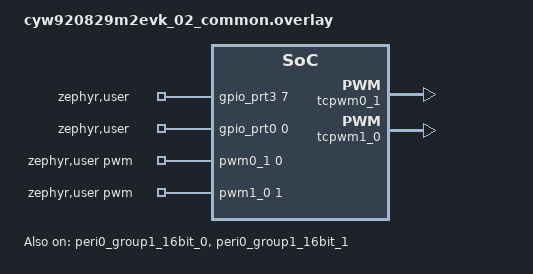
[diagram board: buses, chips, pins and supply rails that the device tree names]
/*
 * Copyright (c) 2025 Infineon Technologies AG,
 * or an affiliate of Infineon Technologies AG.
 *
 * SPDX-License-Identifier: Apache-2.0
 */

#include <zephyr/dt-bindings/pwm/pwm.h>
#include <zephyr/dt-bindings/pwm/pwm_ifx_tcpwm.h>

/ {
	zephyr,user {
		pwms = <&pwm0_1 0 PWM_MSEC(2) (PWM_POLARITY_NORMAL | PWM_IFX_TCPWM_OUTPUT_HIGHZ)>,
		       <&pwm1_0 1 PWM_MSEC(2) (PWM_POLARITY_NORMAL | PWM_IFX_TCPWM_OUTPUT_HIGHZ)>;
		gpios = <&gpio_prt3 7 GPIO_ACTIVE_HIGH>,
			<&gpio_prt0 0 GPIO_ACTIVE_HIGH>;
	};
};

&tcpwm0_1 {
	status = "okay";

	pwm0_1: pwm0_1 {
		status = "okay";
		clocks = <&peri0_group1_16bit_0>;
		pinctrl-0 = <&p3_6_pwm0_1>;
		pinctrl-names = "default";
	};
};

&peri0_group1_16bit_0 {
	status = "okay";
	resource-type = <IFX_RSC_TCPWM>;
	resource-instance = <0>;
	resource-channel = <1>;
	clock-div = <9600>;
};

&tcpwm1_0 {
	status = "okay";

	pwm1_0: pwm1_0 {
		status = "okay";
		clocks = <&peri0_group1_16bit_1>;
		pinctrl-0 = <&p0_1_pwm1_0>;
		pinctrl-names = "default";
	};
};

&peri0_group1_16bit_1 {
	status = "okay";
	resource-type = <IFX_RSC_TCPWM>;
	resource-instance = <1>;
	resource-channel = <0>;
	clock-div = <9600>;
};

&pinctrl {
	p3_6_pwm0_1: p3_6_pwm0_1 {
		drive-push-pull;
	};

	p0_1_pwm1_0: p0_1_pwm1_0 {
		drive-push-pull;
	};
};
